# earlgrey register map
File version: 0.1
Address unit: 32 bits
Registers are 32-bit, read-write, no defined reset value unless marked. A register's access mark holds for its fields unless they carry their own. Offsets are from the block's base; [hi:lo] are bit positions.

## i2c0 — I2C interface for host and device mode, supporting up to 1 Mbaud data rates
Base 0x40080000
Same registers: i2c1 0x40090000, i2c2 0x400A0000
0x00 CTRL — I2C control register (Functions TBD)
  [?] ENABLEHOST — Enable Host I2C functionality
  [?] ENABLETARGET — Enable Target I2C functionality
  [?] LLPBK — Enable I2C line loopback testIf line loopback is enabled, the internal design sees ACQ and RX data as "1"
0x20 STATUS ro — I2C live status register
  [?] FMTFULL — FMT FIFO is full
  [?] RXFULL — RX FIFO is full
  [?] FMTEMPTY — FMT FIFO is empty
  [?] RXEMPTY — RX FIFO is empty
  [?] HOSTIDLE — Host functionality is idle. No Host transaction is in progress
  [?] TARGETIDLE — Target functionality is idle. No Target transaction is in progress
  [?] TXFULL — TX FIFO is full
  [?] ACQFULL — ACQ FIFO is full
  [?] TXEMPTY — TX FIFO is empty
  [?] ACQEMPTY — ACQ FIFO is empty
0x40 RDATA ro — I2C read data
  [7:0] ?
0x60 FDATA wo — I2C Format Data
  [7:0] FBYTE — Format Byte. Directly transmitted if no flags are set.
  [?] START — Issue a START condition before transmitting BYTE.
  [?] STOP — Issue a STOP condition after this operation
  [?] READ — Read BYTE bytes from I2C. (256 if BYTE==0)
  [?] RCONT — Do not NAK the last byte read, let the read operation continue
  [?] NAKOK — Do not signal an exception if the current byte is not ACK'd
0x80 FIFO_CTRL — I2C FIFO control register
  [6:5] FMTILVL — Trigger level for FMT interrupts. If the FIFO depth falls belowthis setting, it raises fmt_threshold interrupt.
    0=fmtlvl1 (1 character); 1=fmtlvl4 (4 characters); 2=fmtlvl8 (8 characters); 3=fmtlvl16 (16 characters)
  [4:2] RXILVL — Trigger level for RX interrupts. If the FIFO depth exceedsthis setting, it raises rx_threshold interrupt.
    0=rxlvl1 (1 character); 1=rxlvl4 (4 characters); 2=rxlvl8 (8 characters); 3=rxlvl16 (16 characters); 4=rxlvl30 (30 characters)
  [?] RXRST — RX fifo reset. Write 1 to the register resets RX_FIFO. Read returns 0
  [?] FMTRST — FMT fifo reset. Write 1 to the register resets FMT_FIFO. Read returns 0
  [?] ACQRST — ACQ FIFO reset. Write 1 to the register resets it. Read returns 0
  [?] TXRST — TX FIFO reset. Write 1 to the register resets it. Read returns 0
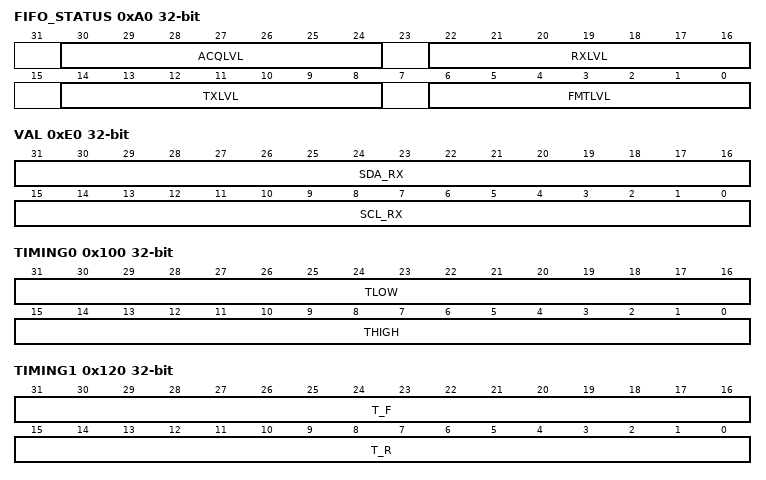
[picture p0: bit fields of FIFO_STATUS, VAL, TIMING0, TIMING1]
0xA0 FIFO_STATUS ro — I2C FIFO status register
  [30:24] ACQLVL — Current fill level of ACQ fifo
  [22:16] RXLVL — Current fill level of RX fifo
  [14:8] TXLVL — Current fill level of TX fifo
  [6:0] FMTLVL — Current fill level of FMT fifo
0xC0 OVRD — I2C override control register
  [?] TXOVRDEN — Override the SDA and SCL TX signals.
  [?] SCLVAL — Value for SCL Override. Set to 0 to drive TX Low, and set to 1 for high-Z
  [?] SDAVAL — Value for SDA Override. Set to 0 to drive TX Low, and set to 1 for high-Z
0xE0 VAL ro — Oversampled RX values
  [31:16] SDA_RX — Last 16 oversampled values of SDA. Most recent bit is bit 16, oldest 31.
  [15:0] SCL_RX — Last 16 oversampled values of SCL. Most recent bit is bit 0, oldest 15.
0x100 TIMING0 — Detailed I2C Timings (directly corresponding to table 10 in the I2C Specification).All values are expressed in units of the input clock period.
  [31:16] TLOW — The actual time to hold SCL low between any two SCL pulses
  [15:0] THIGH — The actual time to hold SCL high in a given pulse
0x120 TIMING1 — Detailed I2C Timings (directly corresponding to table 10 in the I2C Specification).All values are expressed in units of the input clock period.
  [31:16] T_F — The nominal fall time to anticipate for the bus (influences SDA hold times)
  [15:0] T_R — The nominal rise time to anticipate for the bus (depends on capacitance)
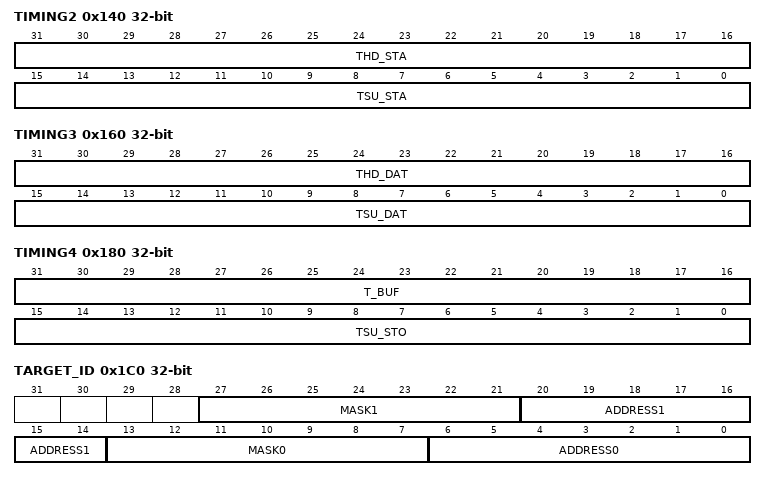
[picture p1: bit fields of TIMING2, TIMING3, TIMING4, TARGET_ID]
0x140 TIMING2 — Detailed I2C Timings (directly corresponding to table 10 in the I2C Specification).All values are expressed in units of the input clock period.
  [31:16] THD_STA — Actual hold time for start signals
  [15:0] TSU_STA — Actual setup time for repeated start signals
0x160 TIMING3 — Detailed I2C Timings (directly corresponding to table 10, in the I2C Specification).All values are expressed in units of the input clock period.
  [31:16] THD_DAT — Actual hold time for data (or ack) bits(Note, where required, the parameters TVD_DAT is taken to be THD_DAT+T_F)
  [15:0] TSU_DAT — Actual setup time for data (or ack) bits
0x180 TIMING4 — Detailed I2C Timings (directly corresponding to table 10, in the I2C Specification).All values are expressed in units of the input clock period.
  [31:16] T_BUF — Actual time between each STOP signal and the following START signal
  [15:0] TSU_STO — Actual setup time for stop signals
0x1A0 TIMEOUT_CTRL — I2C clock stretching timeout control
  [30:0] VAL — Clock stretching timeout value (in units of input clock frequency)
  [?] EN — Enable timeout feature
0x1C0 TARGET_ID — I2C target address and mask pairs
  [27:21] MASK1 — I2C target mask number 1
  [20:14] ADDRESS1 — I2C target address number 1
  [13:7] MASK0 — I2C target mask number 0
  [6:0] ADDRESS0 — I2C target address number 0
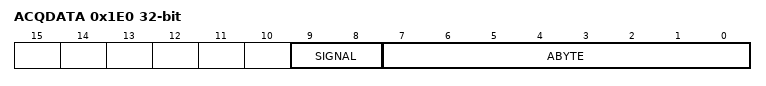
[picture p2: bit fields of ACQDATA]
0x1E0 ACQDATA ro — I2C target acquired data
  [9:8] SIGNAL — Host issued a START before transmitting ABYTE, a STOP or a RESTART after the preceeding ABYTE
  [7:0] ABYTE — Address for accepted transaction or acquired byte
0x200 TXDATA wo — I2C target transmit data
  [7:0] ?
0x220 HOST_TIMEOUT_CTRL — I2C host clock generation timeout value (in units of input clock frequency)
  [31:0] ?
